VERSION ""

NS_ :

BS_:

BU_: CCU GTW SUT

BO_ 293 CCU_125: 2 CCU
 SG_ Signal_9 : 8|8@1- (1,0) [0|0] ""  SUT
 SG_ Signal_8 : 0|8@1- (1,0) [0|0] ""  SUT

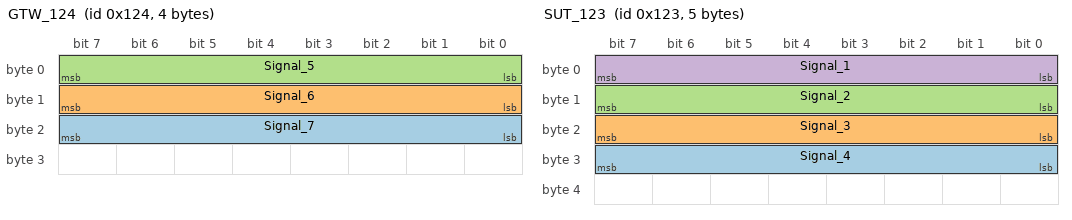
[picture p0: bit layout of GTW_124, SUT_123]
BO_ 292 GTW_124: 4 GTW
 SG_ Signal_7 : 16|8@1- (1,0) [0|0] ""  CCU,SUT
 SG_ Signal_6 : 8|8@1- (1,0) [0|0] ""  CCU,SUT
 SG_ Signal_5 : 0|8@1- (1,0) [0|0] ""  CCU,SUT

BO_ 291 SUT_123: 5 SUT
 SG_ Signal_4 : 24|8@1- (1,0) [0|0] ""  CCU,GTW
 SG_ Signal_3 : 16|8@1- (1,0) [0|0] ""  CCU,GTW
 SG_ Signal_2 : 8|8@1- (1,0) [0|0] ""  CCU,GTW
 SG_ Signal_1 : 0|8@1- (1,0) [0|0] ""  CCU,GTW

BA_DEF_ BO_  "GenMsgCycleTime" INT 0 65535;
BA_DEF_DEF_  "GenMsgCycleTime" 0;
BA_ "GenMsgCycleTime" BO_ 293 10;
BA_ "GenMsgCycleTime" BO_ 292 20;
BA_ "GenMsgCycleTime" BO_ 291 100;
